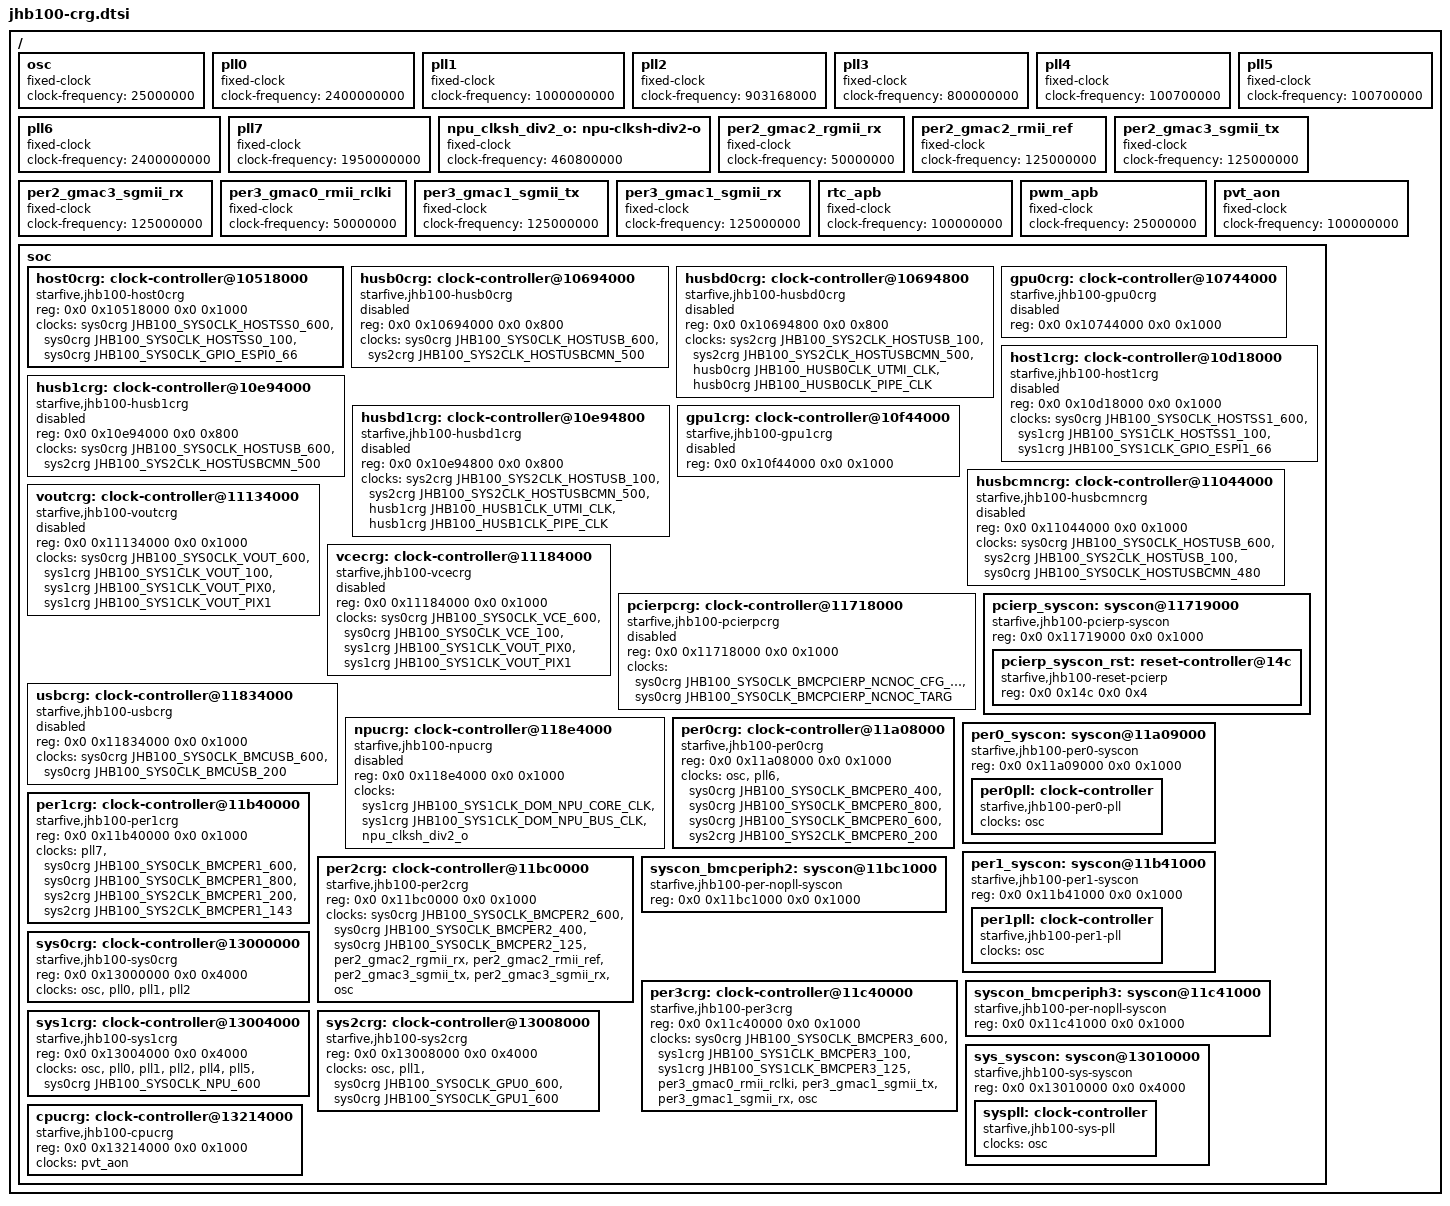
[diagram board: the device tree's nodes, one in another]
// SPDX-License-Identifier: GPL-2.0 OR MIT
/*
 * Copyright (c) 2024 StarFive Technology Co., Ltd.
 */

#include <dt-bindings/clock/starfive,jhb100-crg.h>
#include <dt-bindings/reset/starfive,jhb100-crg.h>

/ {
	osc: osc {
		compatible = "fixed-clock";
		#clock-cells = <0>;
		clock-frequency = <25000000>;
	};

	pll0: pll0 {
		compatible = "fixed-clock";
		#clock-cells = <0>;
		clock-frequency = <2400000000>;
	};

	pll1: pll1 {
		compatible = "fixed-clock";
		#clock-cells = <0>;
		clock-frequency = <1000000000>;
	};

	pll2: pll2 {
		compatible = "fixed-clock";
		#clock-cells = <0>;
		clock-frequency = <903168000>;
	};

	pll3: pll3 {
		compatible = "fixed-clock";
		#clock-cells = <0>;
		clock-frequency = <800000000>;
	};

	pll4: pll4 {
		compatible = "fixed-clock";
		#clock-cells = <0>;
		clock-frequency = <100700000>;
	};

	pll5: pll5 {
		compatible = "fixed-clock";
		#clock-cells = <0>;
		clock-frequency = <100700000>;
	};

	pll6: pll6 {
		compatible = "fixed-clock";
		#clock-cells = <0>;
		clock-frequency = <2400000000>;
	};

	pll7: pll7 {
		compatible = "fixed-clock";
		#clock-cells = <0>;
		clock-frequency = <1950000000>;
	};

	npu_clksh_div2_o: npu-clksh-div2-o {
		compatible = "fixed-clock";
		#clock-cells = <0>;
		clock-frequency = <460800000>;
	};

	per2_gmac2_rgmii_rx: per2_gmac2_rgmii_rx {
		compatible = "fixed-clock";
		#clock-cells = <0>;
		clock-frequency = <50000000>;
	};

	per2_gmac2_rmii_ref: per2_gmac2_rmii_ref {
		compatible = "fixed-clock";
		#clock-cells = <0>;
		clock-frequency = <125000000>;
	};

	per2_gmac3_sgmii_tx: per2_gmac3_sgmii_tx {
		compatible = "fixed-clock";
		#clock-cells = <0>;
		clock-frequency = <125000000>;
	};

	per2_gmac3_sgmii_rx: per2_gmac3_sgmii_rx {
		compatible = "fixed-clock";
		#clock-cells = <0>;
		clock-frequency = <125000000>;
	};

	per3_gmac0_rmii_rclki: per3_gmac0_rmii_rclki {
		compatible = "fixed-clock";
		#clock-cells = <0>;
		clock-frequency = <50000000>;
	};

	per3_gmac1_sgmii_tx: per3_gmac1_sgmii_tx {
		compatible = "fixed-clock";
		#clock-cells = <0>;
		clock-frequency = <125000000>;
	};

	per3_gmac1_sgmii_rx: per3_gmac1_sgmii_rx {
		compatible = "fixed-clock";
		#clock-cells = <0>;
		clock-frequency = <125000000>;
	};

	rtc_apb: rtc_apb {
		compatible = "fixed-clock";
		#clock-cells = <0>;
		clock-frequency = <100000000>;
	};

	pwm_apb: pwm_apb {
		compatible = "fixed-clock";
		#clock-cells = <0>;
		clock-frequency = <25000000>;
	};

	pvt_aon: pvt_aon {
		compatible = "fixed-clock";
		#clock-cells = <0>;
		clock-frequency = <100000000>;
	};

	soc {
		host0crg: clock-controller@10518000 {
			compatible = "starfive,jhb100-host0crg";
			reg = <0x0 0x10518000 0x0 0x1000>;
			clocks = <&sys0crg JHB100_SYS0CLK_HOSTSS0_600>,
				 <&sys0crg JHB100_SYS0CLK_HOSTSS0_100>,
				 <&sys0crg JHB100_SYS0CLK_GPIO_ESPI0_66>;
			clock-names = "host0_600", "host0_100",
				      "host0_espi0_66";
			#clock-cells = <1>;
			#reset-cells = <1>;
			status = "okay";
		};

		husb0crg: clock-controller@10694000 {
			compatible = "starfive,jhb100-husb0crg";
			reg = <0x0 0x10694000 0x0 0x800>;
			clocks = <&sys0crg JHB100_SYS0CLK_HOSTUSB_600>,
				 <&sys2crg JHB100_SYS2CLK_HOSTUSBCMN_500>;
			clock-names = "husb0_600", "husb0_500";
			#clock-cells = <1>;
			#reset-cells = <1>;
			status = "disabled";
		};

		husbd0crg: clock-controller@10694800 {
			compatible = "starfive,jhb100-husbd0crg";
			reg = <0x0 0x10694800 0x0 0x800>;
			clocks = <&sys2crg JHB100_SYS2CLK_HOSTUSB_100>,
				 <&sys2crg JHB100_SYS2CLK_HOSTUSBCMN_500>,
				 <&husb0crg JHB100_HUSB0CLK_UTMI_CLK>,
				 <&husb0crg JHB100_HUSB0CLK_PIPE_CLK>;
			clock-names = "husbd0_100", "husbd0_500",
				      "husbd0_utmi_clk", "husbd0_pipe_clk";
			#clock-cells = <1>;
			#reset-cells = <1>;
			status = "disabled";
		};

		gpu0crg: clock-controller@10744000 {
			compatible = "starfive,jhb100-gpu0crg";
			reg = <0x0 0x10744000 0x0 0x1000>;
			#clock-cells = <1>;
			#reset-cells = <1>;
			status = "disabled";
		};

		host1crg: clock-controller@10d18000 {
			compatible = "starfive,jhb100-host1crg";
			reg = <0x0 0x10d18000 0x0 0x1000>;
			clocks = <&sys0crg JHB100_SYS0CLK_HOSTSS1_600>,
				 <&sys1crg JHB100_SYS1CLK_HOSTSS1_100>,
				 <&sys1crg JHB100_SYS1CLK_GPIO_ESPI1_66>;
			clock-names = "host1_600", "host1_100",
				      "host1_espi1_66";
			#clock-cells = <1>;
			#reset-cells = <1>;
			status = "disabled";
		};

		husb1crg: clock-controller@10e94000 {
			compatible = "starfive,jhb100-husb1crg";
			reg = <0x0 0x10e94000 0x0 0x800>;
			clocks = <&sys0crg JHB100_SYS0CLK_HOSTUSB_600>,
				 <&sys2crg JHB100_SYS2CLK_HOSTUSBCMN_500>;
			clock-names = "husb1_600", "husb1_500";
			#clock-cells = <1>;
			#reset-cells = <1>;
			status = "disabled";
		};

		husbd1crg: clock-controller@10e94800 {
			compatible = "starfive,jhb100-husbd1crg";
			reg = <0x0 0x10e94800 0x0 0x800>;
			clocks = <&sys2crg JHB100_SYS2CLK_HOSTUSB_100>,
				 <&sys2crg JHB100_SYS2CLK_HOSTUSBCMN_500>,
				 <&husb1crg JHB100_HUSB1CLK_UTMI_CLK>,
				 <&husb1crg JHB100_HUSB1CLK_PIPE_CLK>;
			clock-names = "husbd1_100", "husbd1_500",
				      "husbd1_utmi_clk", "husbd1_pipe_clk";
			#clock-cells = <1>;
			#reset-cells = <1>;
			status = "disabled";
		};

		gpu1crg: clock-controller@10f44000 {
			compatible = "starfive,jhb100-gpu1crg";
			reg = <0x0 0x10f44000 0x0 0x1000>;
			#clock-cells = <1>;
			#reset-cells = <1>;
			status = "disabled";
		};

		husbcmncrg: clock-controller@11044000 {
			compatible = "starfive,jhb100-husbcmncrg";
			reg = <0x0 0x11044000 0x0 0x1000>;
			clocks = <&sys0crg JHB100_SYS0CLK_HOSTUSB_600>,
				 <&sys2crg JHB100_SYS2CLK_HOSTUSB_100>,
				 <&sys0crg JHB100_SYS0CLK_HOSTUSBCMN_480>;
			clock-names = "husbcmn_husb_600", "husbcmn_husb_100",
				      "husbcmn_480";
			#clock-cells = <1>;
			#reset-cells = <1>;
			status = "disabled";
		};

		voutcrg: clock-controller@11134000 {
			compatible = "starfive,jhb100-voutcrg";
			reg = <0x0 0x11134000 0x0 0x1000>;
			clocks = <&sys0crg JHB100_SYS0CLK_VOUT_600>,
				 <&sys1crg JHB100_SYS1CLK_VOUT_100>,
				 <&sys1crg JHB100_SYS1CLK_VOUT_PIX0>,
				 <&sys1crg JHB100_SYS1CLK_VOUT_PIX1>;
			clock-names = "vout_600", "vout_100",
				      "vout_pix0", "vout_pix1";
			#clock-cells = <1>;
			#reset-cells = <1>;
			status = "disabled";
		};

		vcecrg: clock-controller@11184000 {
			compatible = "starfive,jhb100-vcecrg";
			reg = <0x0 0x11184000 0x0 0x1000>;
			clocks = <&sys0crg JHB100_SYS0CLK_VCE_600>,
				 <&sys0crg JHB100_SYS0CLK_VCE_100>,
				 <&sys1crg JHB100_SYS1CLK_VOUT_PIX0>,
				 <&sys1crg JHB100_SYS1CLK_VOUT_PIX1>;
			clock-names = "vce_600", "vce_100", "vce_pix0",
				      "vce_pix1";
			#clock-cells = <1>;
			#reset-cells = <1>;
			status = "disabled";
		};

		pcierpcrg: clock-controller@11718000 {
			compatible = "starfive,jhb100-pcierpcrg";
			reg = <0x0 0x11718000 0x0 0x1000>;
			clocks = <&sys0crg JHB100_SYS0CLK_BMCPCIERP_NCNOC_CFG_INIT>,
				 <&sys0crg JHB100_SYS0CLK_BMCPCIERP_NCNOC_TARG>;
			clock-names = "pcierp_nonoc_cfg_init",
				      "pcierp_ncnoc_targ";
			#clock-cells = <1>;
			#reset-cells = <1>;
			status = "disabled";
		};

		pcierp_syscon: syscon@11719000 {
			compatible = "starfive,jhb100-pcierp-syscon", "syscon",
				     "simple-mfd";
			reg = <0x0 0x11719000 0x0 0x1000>;
			#address-cells = <2>;
			#size-cells = <2>;
			ranges = <0x0 0x0 0x0 0x11719000 0x0 0x1000>;

			pcierp_syscon_rst: reset-controller@14c {
				compatible = "starfive,jhb100-reset-pcierp";
				reg = <0x0 0x14c 0x0 0x4>;
				#reset-cells = <1>;
			};
		};

		usbcrg: clock-controller@11834000 {
			compatible = "starfive,jhb100-usbcrg";
			reg = <0x0 0x11834000 0x0 0x1000>;
			clocks = <&sys0crg JHB100_SYS0CLK_BMCUSB_600>,
				 <&sys0crg JHB100_SYS0CLK_BMCUSB_200>;
			clock-names = "usb_600", "usb_200";
			#clock-cells = <1>;
			#reset-cells = <1>;
			status = "disabled";
		};

		npucrg: clock-controller@118e4000 {
			compatible = "starfive,jhb100-npucrg";
			reg = <0x0 0x118e4000 0x0 0x1000>;
			clocks = <&sys1crg JHB100_SYS1CLK_DOM_NPU_CORE_CLK>,
				 <&sys1crg JHB100_SYS1CLK_DOM_NPU_BUS_CLK>,
				 <&npu_clksh_div2_o>;
			clock-names = "npu_dom_core_clk", "npu_dom_bus_clk",
				      "npu_clksh_div2_o";
			#clock-cells = <1>;
			#reset-cells = <1>;
			status = "disabled";
		};

		per0crg: clock-controller@11a08000 {
			compatible = "starfive,jhb100-per0crg";
			reg = <0x0 0x11a08000 0x0 0x1000>;
			clocks = <&osc>, <&pll6>,
				 <&sys0crg JHB100_SYS0CLK_BMCPER0_400>,
				 <&sys0crg JHB100_SYS0CLK_BMCPER0_800>,
				 <&sys0crg JHB100_SYS0CLK_BMCPER0_600>,
				 <&sys2crg JHB100_SYS2CLK_BMCPER0_200>;
			clock-names = "osc", "pll6", "per0_400",
				      "per0_800", "per0_600",
				      "per0_200_init";
			#clock-cells = <1>;
			#reset-cells = <1>;
		};

		per0_syscon: syscon@11a09000 {
			compatible = "starfive,jhb100-per0-syscon", "syscon",
				     "simple-mfd";
			reg = <0x0 0x11a09000 0x0 0x1000>;

			per0pll: clock-controller {
				compatible = "starfive,jhb100-per0-pll";
				clocks = <&osc>;
				#clock-cells = <1>;
			};
		};

		per1crg: clock-controller@11b40000 {
			compatible = "starfive,jhb100-per1crg";
			reg = <0x0 0x11b40000 0x0 0x1000>;
			clocks = <&pll7>,
				 <&sys0crg JHB100_SYS0CLK_BMCPER1_600>,
				 <&sys0crg JHB100_SYS0CLK_BMCPER1_800>,
				 <&sys2crg JHB100_SYS2CLK_BMCPER1_200>,
				 <&sys2crg JHB100_SYS2CLK_BMCPER1_143>;
			clock-names = "pll7", "per1_600",
				      "per1_800", "per1_200",
				      "per1_143";
			#clock-cells = <1>;
			#reset-cells = <1>;
		};

		per1_syscon: syscon@11b41000 {
			compatible = "starfive,jhb100-per1-syscon", "syscon",
				     "simple-mfd";
			reg = <0x0 0x11b41000 0x0 0x1000>;

			per1pll: clock-controller {
				compatible = "starfive,jhb100-per1-pll";
				clocks = <&osc>;
				#clock-cells = <1>;
			};
		};

		per2crg: clock-controller@11bc0000 {
			compatible = "starfive,jhb100-per2crg";
			reg = <0x0 0x11bc0000 0x0 0x1000>;
			clocks = <&sys0crg JHB100_SYS0CLK_BMCPER2_600>,
				 <&sys0crg JHB100_SYS0CLK_BMCPER2_400>,
				 <&sys0crg JHB100_SYS0CLK_BMCPER2_125>,
				 <&per2_gmac2_rgmii_rx>,
				 <&per2_gmac2_rmii_ref>,
				 <&per2_gmac3_sgmii_tx>,
				 <&per2_gmac3_sgmii_rx>,
				 <&osc>;
			clock-names = "per2_600", "per2_400", "per2_125",
				      "per2_gmac2_rgmii_rx",
				      "per2_gmac2_rmii_ref",
				      "per2_gmac3_sgmii_tx",
				      "per2_gmac3_sgmii_rx",
				      "osc";
			#clock-cells = <1>;
			#reset-cells = <1>;
		};

		syscon_bmcperiph2: syscon@11bc1000 {
			compatible = "starfive,jhb100-per-nopll-syscon", "syscon";
			reg = <0x0 0x11bc1000 0x0 0x1000>;
		};

		per3crg: clock-controller@11c40000 {
			compatible = "starfive,jhb100-per3crg";
			reg = <0x0 0x11c40000 0x0 0x1000>;
			clocks = <&sys0crg JHB100_SYS0CLK_BMCPER3_600>,
				 <&sys1crg JHB100_SYS1CLK_BMCPER3_100>,
				 <&sys1crg JHB100_SYS1CLK_BMCPER3_125>,
				 <&per3_gmac0_rmii_rclki>,
				 <&per3_gmac1_sgmii_tx>,
				 <&per3_gmac1_sgmii_rx>,
				 <&osc>;
			clock-names = "per3_600", "per3_100", "per3_125",
				      "per3_gmac0_rmii_rclki",
				      "per3_gmac1_sgmii_tx",
				      "per3_gmac1_sgmii_rx",
				      "osc";
			#clock-cells = <1>;
			#reset-cells = <1>;
		};

		syscon_bmcperiph3: syscon@11c41000 {
			compatible = "starfive,jhb100-per-nopll-syscon", "syscon";
			reg = <0x0 0x11c41000 0x0 0x1000>;
		};

		sys0crg: clock-controller@13000000 {
			compatible = "starfive,jhb100-sys0crg";
			reg = <0x0 0x13000000 0x0 0x4000>;
			clocks = <&osc>, <&pll0>, <&pll1>, <&pll2>;
			clock-names = "osc", "pll0", "pll1", "pll2";
			#clock-cells = <1>;
			#reset-cells = <1>;
		};

		sys1crg: clock-controller@13004000 {
			compatible = "starfive,jhb100-sys1crg";
			reg = <0x0 0x13004000 0x0 0x4000>;
			clocks = <&osc>, <&pll0>, <&pll1>, <&pll2>,
				 <&pll4>, <&pll5>, <&sys0crg JHB100_SYS0CLK_NPU_600>;
			clock-names = "osc", "pll0", "pll1", "pll2",
				      "pll4", "pll5", "sys1_npu_600";
			#clock-cells = <1>;
			#reset-cells = <1>;
		};

		sys2crg: clock-controller@13008000 {
			compatible = "starfive,jhb100-sys2crg";
			reg = <0x0 0x13008000 0x0 0x4000>;
			clocks = <&osc>, <&pll1>,
				 <&sys0crg JHB100_SYS0CLK_GPU0_600>,
				 <&sys0crg JHB100_SYS0CLK_GPU1_600>;
			clock-names = "osc", "pll1", "sys2_gpu0_600",
				      "sys2_gpu1_600";
			#clock-cells = <1>;
			#reset-cells = <1>;
		};

		sys_syscon: syscon@13010000 {
			compatible = "starfive,jhb100-sys-syscon", "syscon",
				     "simple-mfd";
			reg = <0x0 0x13010000 0x0 0x4000>;

			syspll: clock-controller {
				compatible = "starfive,jhb100-sys-pll";
				clocks = <&osc>;
				#clock-cells = <1>;
			};
		};

		cpucrg: clock-controller@13214000 {
			compatible = "starfive,jhb100-cpucrg";
			reg = <0x0 0x13214000 0x0 0x1000>;
			clocks = <&pvt_aon>;
			clock-names = "cpu_sensor";
			#clock-cells = <1>;
			#reset-cells = <1>;
		};
	};
};
